# ISP6P5_RESIZER register map
Vendor: Texas Instruments
Peripheral module from a debugger description file (folder DRA74xP_75xP_76xP_77xP).
Registers are 32-bit, access per field, reset 0x0 unless marked. A register's access mark holds for its fields unless they carry their own. Offsets are as the file gives them; lines under a group give offsets from that group; [hi:lo] are bit positions; {n}, {i} and the like mark numbered series; 'fields as' and 'values as' point back to an identical list; <NAME> marks a mode.

## ISP6P5_RESIZER
0x00 RSZ_REVISION ro reset not defined — IP Revision Identifier (X.Y.R) Used by software to track features, bugs, and compatibility
  [31:0] REVISION — IP Revision
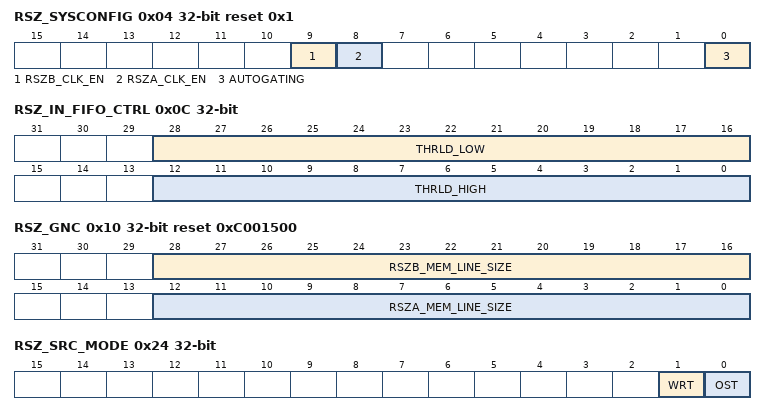
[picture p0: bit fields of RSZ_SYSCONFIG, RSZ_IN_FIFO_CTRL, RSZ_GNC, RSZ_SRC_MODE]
0x04 RSZ_SYSCONFIG reset 0x1 — SYSTEM CONFIGURATION REGISTER This register is not shadowed. There is no standalone software reset for the resizer module.
  [9] RSZB_CLK_EN rw — Resizer B clock enable This bit enable to enable / disable the RESIZER B clock. Note that it is a second level clock enable. This bit has effect only ifRSZ_GCK_SDR is set to '1'.
    0=NEWENUM1 (off); 1=NEWENUM2 (on)
  [8] RSZA_CLK_EN rw — Resizer A clock enable This bit enable to enable / disable the RESIZER A clock. Note that it is a second level clock enable. This bit has effect only ifRSZ_GCK_SDR is set to '1'.
    0=NEWENUM1 (off); 1=NEWENUM2 (on)
  [0] AUTOGATING rw — Internal Clock Gating Strategy Enables or disables auto clock gating.
    0=NEWENUM1 (Clocks are free running); 1=NEWENUM2 (Automatic clock gating strategy.)
0x08 RSZ_SYSSTATUS ro — SYSTEM STATUS REGISTER This register is not shadowed
0x0C RSZ_IN_FIFO_CTRL — INPUT DATA BUFFER CONTROL REGISTER This register is not shadowed
  [28:16] THRLD_LOW rw — WhenRSZ_IN_FIFO_CTRL.THRLD_HIGH = RSZ_IN_FIFO_CTRL.THRLD_LOW, the rsz_stall_input is not asserted. The only purpose of the RSZ_IN_FIFO_CTRL.THRLD_LOW register is to prevent rsz_stall_input signal assertion.
  [12:0] THRLD_HIGH rw — High threshold value. The rsz_stall_input signal is asserted if 2 lines of circular buffer are full and the third line has more pixels thanRSZ_IN_FIFO_CTRL.THRLD_HIGH. The rsz_stall_input signal stays high as long as one full line is not free for receiving further data. THRLD_HIGH is in terms of line size and can at max be programmed equal to the input line size (RSZ_SRC_HSZ).
0x10 RSZ_GNC ro reset 0xC001500 — GENERIC PARAMETER REGISTER
  [28:16] RSZB_MEM_LINE_SIZE — Resizer #B memory line size (pixels). The output image cannot exceed this size.
  [12:0] RSZA_MEM_LINE_SIZE — Resizer #A memory line size (pixels). The output image cannot excced this size.
0x14 RSZ_FRACDIV reset 0xFFFF — Fractional clock divider settings
  [15:0] RSZ_FRACDIV rw — Fractional clock divider value. The fractional clock divider gates the read requests made to the input data buffer such that the input data buffer is read at an average frequency equal to FFCLK instead of FCLK. The value of FFCLK depends upon the upscaling ratios as well as the input pixel clock: refer to the functional spec. We have FFCLK = FCLK / FRACDIV MHz andRSZ_FRACDIV = 65536 / FRACDIV. When RSZ_ FRACDIV = 65536, we have: FFCLK = FCLK.
0x20 RSZ_SRC_EN — RESIZER ENABLE REGISTER This register is not shadowed
  [0] EN rw — Resizer module enable The start flag of the RESIZER module. When EN is set to '1', the RESIZER module starts the processing from the next rising edge of the VD pulse. If the processing mode of the RESIZER module is set to 'one shot', the EN bit is cleared to '0' after the end of the processing. One has to pay attention that when this bit is enabled and
    0=NEWENUM1 (Disable); 1=NEWENUM2 (Enable)
0x24 RSZ_SRC_MODE — This register is not shadowed
  [1] WRT rw — Video port WEN signal selection This bit selects whether the WEN signal which is present on the IPIPE and IPIPEIF video port is used or not to select the input data. If WRT is 0, the RESIZER module ignores the WEN signal and processes all image frame while RESIZER is enabled. If WRT is 1, the RESIZER module only processes the lines that arrived while the WEN is high. HD is used to sample the WEN signal.
    0=NEWENUM1 (Disable); 1=NEWENUM2 (Enable)
  [0] OST rw — The processing mode selection of the RESIZER module. Value 0 indicates the mode of ?free run?, value 1 indicates the mode of ?one shot'.
    0=NEWENUM1 (Free running); 1=NEWENUM2 (One shot)
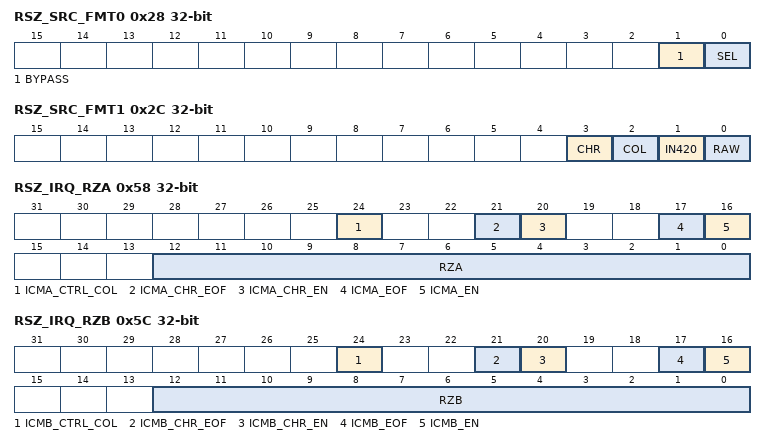
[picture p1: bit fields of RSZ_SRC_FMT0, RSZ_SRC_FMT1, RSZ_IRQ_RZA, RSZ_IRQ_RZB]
0x28 RSZ_SRC_FMT0 — This register is not shadowed
  [1] BYPASS rw — Pass Through This bit enables or disables the RESIZER module pass through mode. The pass trhough mode can transfer images which are 8K pixel wide. When it is enabled, the input data buffer and the resizer engines are bypassed.
    0=NEWENUM1 (Pass through off = normal output mode, the input data buffer is used.); 1=NEWENUM2 (Pass through on = normal output mode, the input data buffer is bypassed.)
  [0] SEL rw — Input selection This bit selects which of the two video port is selected to push data through the RESIZER module.
    0=NEWENUM1 (IPIPE); 1=SRC (IPIPEIF)
0x2C RSZ_SRC_FMT1
  [3] CHR rw — Cb/Cr order Note: This is only for OMA5430 This bit indicates if Cb/Cr is flipped. This bit is reffered by RGB output function. 0: Normal. Cb/Cr is in normal order. 1: Flipped. Cb/Cr is flipped. RGB output modules flips back Cb/Cr before applying YUV to RGB matrix.
    0=NORMAL (Cb/Cr is in normal order.); 1=FLIPPED (Cb/Cr is flipped. RGB output modules flips back Cb/Cr before applying YUV to RGB matrix.)
  [2] COL rw — Y/C selection This bit is valid only if the input data is YUV420 (IN420 = '1'). It enables to specify where the data which is input to the RESIZER module is luma or chroma data.
    0=NEWENUM1 (Y data is input); 1=NEWENUM2 (Chroma data is input)
  [1] IN420 rw — Chroma Format Selection This bit sets the chroma undersampling when YUV data is input to the RESIZER module.
    0=NEWENUM1 (YUV422 is input); 1=NEWENUM2 (YUV420 is input)
  [0] RAW rw — Pass-through mode input data format selection This bit affects the horizontal reversal (flipping) process.
    0=NEWENUM1 (Flipping preserves YCbCr format); 1=NEWENUM2 (Flipping preserves RAW format)
0x30 RSZ_SRC_VPS — VERTICAL POSITION REGISTER This register is not shadowed
  [15:0] VPS rw — Vertical Start Position Sets the vertical position of the global frame from the rising edge of the VD. The RSZ module will start the image processing from the VPS'th line. This value can be odd or even whatever the input data format.
0x34 RSZ_SRC_VSZ — VERTICAL SIZER REGISTER
  [12:0] VSZ rw — Vertical Processing Size Sets the vertical size of the processing area. The RSZ module will process (VSZ+1) lines. This value can be odd or even whatever the input data format.
0x38 RSZ_SRC_HPS — HORIZONTAL POSITION REGISTER This register is not shadowed
  [15:0] HPS rw — Horizontal Start Position TheRSZ_SRC_HPS register has two functions. The first function is to compensate for possible delay btw the HD pulse and the first valid data, it is possible that this delay be different of 0 when the RESIZER module gets its input data from the VPORT connected to the IPIPEIF module (the offset value can be odd or even). When data are coming from the IPIPE module, it is never required to resynchronize HD and first valid data. The second function is to crop the data in the horizontal direction. When used for cropping only RSZ_SRC_HPS shall be even or null.
0x3C RSZ_SRC_HSZ — HORIZONTAL SIZE REGISTER The HSZ value is given by HSZ concatenated with HSZ_LSB
  [12:0] HSZ rw — Horizontal size Sets the horizontal size of the processing area. The RSZ module processes (HSZ+1) pixels. (HSZ+1) shall be even for YUV422 and RAW data.
0x40 RSZ_DMA_RZA — RESIZER A - MEMORY REQUEST MINIMUM INTERVAL REGISTER
  [15:0] RZA rw — Sets the minimum inteval btw two consecutive memory request for resizer #A. Specified in number of interface clock cycles. Values of 0, 1, and 2 are used as a condition to keep the bandwidth limiter off. When this function is enabled, this value shall be greater than 10 cycles.
0x44 RSZ_DMA_RZB — RESIZER B - MEMORY REQUEST MINIMUM INTERVAL REGISTER
  [15:0] RZB rw — Sets the minimum inteval btw two consecutive memory request for resizer #B. Specified in number of interface clock cycles. Values of 0, 1, and 2 are used as a condition to keep the bandwidth limiter off. When this function is enabled, this value shall be greater than 10 cycles.
0x48 RSZ_DMA_STA ro — RESIZER STATUS REGISTER
  [0] STATUS — Resizer process status This bit is set in the time window from rsz_int_reg to rsz_int_dma.
    0=NEWENUM1 (Not active); 1=NEWENUM2 (Active)
0x4C RSZ_GCK_MMR — MMR CLOCK CONTROL REGISTER This register is not shadowed
  [0] MMR rw — The on/off selection of the MMR interface clock which is used for MMR register access.
    0=NEWENUM1 (Off); 1=NEWENUM2 (On)
0x54 RSZ_GCK_SDR — CORE CLOCK CONTROL REGISTER This register is not shadowed
  [0] CORE rw — RSZ Core Clock Enable. This bit enables or disables the resizer core functional clock. When this bit is off, the resizer core (interpolator) is automatically bypassed (resizer-bypass mode of pass-through mode is selected depending onRSZ_SRC_FMT0 value). In resizer-bypass mode or pass-through mode, no up-scaling or downscaling process is operated.
    0=NEWENUM1 (Resizer core clock disabled. Resizer in bypass mode if.BYPASS = 0 Resizer in pass-through if .BYPASS = 1); 1=NEWENUM2 (Resizer core clock enabled. Resizer in rescaling mode if.BYPASS = 0 Resizer in pass-through if .BYPASS = 1)
0x58 RSZ_IRQ_RZA — RESIZER A - CIRCULAR BUFFER INTERRUPT INTERVAL REGISTER
  [24] ICMA_CTRL_COL rw — Choose luma done (P_DONE_A) or chroma done (P_DONE_AC) to control
    0=LUMA (RZA processing is controlled by P_START and P_DONE_A (LUMA) This is used for cases not specified in CHROMA case.); 1=CHROMA (RZA processing is based on P_START and P_DONE_AC signal This case is chosen in the following cases - YUV422 input 420-Y+C output with CNF on - YUV422 input 420-C output - YUV420-C input 420-C output)
  [21] ICMA_CHR_EOF rw — Enable the generation of P_DONE_AC pulse at the end of each frame, if the height is not a multiple of RZA. For example, generate a pulse at the end of frme if the height is 1080 and RZA=256. This is only valid if ICMA_CHR_EN='1'
    0=DISABLE (Don't generate a P_DONE_A pulse at the end of frame if the height is not a multiple of RZA); 1=ENABLE (Generate a P_DONE_A pulse at the end of frame if the height is not a multiple of RZA)
  [20] ICMA_CHR_EN rw — Enable hand-shaking with ICM (RSZ-A) in Chroma Channel This is only valid in YUV-420 mode with chroma output. In particular, in the following 2 cases 1. YUV422 input YUV420 outputRSZ_SRC_FMT1.IN420 = 0 (YUV 422 input) RZA_420.CEN = 1 (YUV420 output. Chroma output enabled) ICM cycle is 1/2 of the value specified in RZA 2. YUV420 Chroma input/output RSZ_SRC_FMT1.IN420 = 1 (YUV 420 input) RSZ_SRC_FMT1.COL = 1 (Chroma input) ICM cycle is the cycle specified by RZA
    0=DISABLE (Disable handshake between RSZA and ICM); 1=ENABLE (Enable handshake between RSZA and ICM)
  [17] ICMA_EOF rw — Enable the generation of P_DONE_A pulse at the end of each frame, if the height is not a multiple of RZA. For example, generate a pulse at the end of frme if the height is 1080 and RZA=256. This is only valid if ICMA_EN='1'
    values as ICMA_CHR_EOF
  [16] ICMA_EN rw — Enable hand-shaking with ICM (RSZ-A)
    values as ICMA_CHR_EN
  [12:0] RZA rw — Resizer A circular buffer interval. This value is also used as a ICM-RSZA hand shake interval. Sets the circular buffer interval for Resizer A. The interrupt is triggered everytime (RZA+1) lines are written to the circular buffer (Y buffer). The range goes from 1 to 8192 lines. Usually, the circular buffer vertical size should be a multiple of RZA.
0x5C RSZ_IRQ_RZB — RESIZER B - CIRCULAR BUFFER INTERRUPT INTERVAL REGISTER
  [24] ICMB_CTRL_COL rw — Choose luma done (P_DONE_B) or chroma done (P_DONE_BC) to control
    0=LUMA (RZB processing is controlled by P_START and P_DONE_B (LUMA) This is used for cases not specified in CHROMA case.); 1=CHROMA (RZB processing is based on P_START and P_DONE_BC signal This case is chosen in the following cases - YUV422 input 420-Y+C output with CNF on - YUV422 input 420-C output - YUV420-C input 420-C output)
  [21] ICMB_CHR_EOF rw — Enable the generation of P_DONE_BC pulse at the end of each frame, if the height is not a multiple of RZB. For example, generate a pulse at the end of frme if the height is 1080 and RZB=256. This is only valid if ICMB_CHR_EN='1'
    values as RSZ_IRQ_RZA.ICMA_CHR_EOF
  [20] ICMB_CHR_EN rw — Enable hand-shaking with ICM (RSZ-B) in Chroma Channel This is only valid in YUV-420 mode with chroma output. In particular, in the following 2 cases 1. YUV422 input YUV420 outputRSZ_SRC_FMT1.IN420 = 0 (YUV 422 input) RZB_420.CEN = 1 (YUV420 output. Chroma output enabled) ICM cycle is 1/2 of the value specified in RZB 2. YUV420 Chroma input/output RSZ_SRC_FMT1.IN420 = 1 (YUV 420 input) RSZ_SRC_FMT1.COL = 1 (Chroma input) ICM cycle is the value specified in RZB
    values as RSZ_IRQ_RZA.ICMA_CHR_EN
  [17] ICMB_EOF rw — Enable the generation of P_DONE_B pulse at the end of each frame, if the height is not a multiple of RZB. For example, generate a pulse at the end of frme if the height is 1080 and RZB=256. This is only valid if ICMB_EN='1'
    0=DISABLE (Don't generate a P_DONE_B pulse at the end of frame if the height is not a multiple of RZB.); 1=ENABLE (Generate a P_DONE_B pulse at the end of frame if the height is not a multiple of RZB.)
  [16] ICMB_EN rw — Enalbe handshake between RSZB and ICM
    0=DISABLE (Disable handshake between RSZB and ICM); 1=ENABLE (Enable handshake between RSZB and ICM)
  [12:0] RZB rw — Resizer B circular buffer interval. This value is also used as a ICM-RSZB hand shake interval. Sets the circular buffer interval for Resizer B. The interrupt is triggered everytime (RZB+1) lines are written to the circular buffer (Y buffer). The range goes from 1 to 8192 lines. Usually, the circular buffer vertical size should be a multiple of RZB.
0x60 RSZ_YUV_Y_MIN — LUMINANCE SATURATION REGISTER
  [7:0] MIN rw — The minimum value of Luminance (8bits unsigned). If the value of the Luminance is smaller than VAL, it will be clipped to VAL. This bit field shall be set to its default values when the resizer is set in pass-though mode.
0x64 RSZ_YUV_Y_MAX reset 0xFF — LUMINANCE SATURATION REGISTER
  [7:0] MAX rw — The maximum value of Luminance (8bits unsigned). If the value of the Luminance is larger than VAL, it will be clipped to VAL. This bit field shall be set to its default values when the resizer is set in pass-through mode.
0x68 RSZ_YUV_C_MIN — CHROMINANCE SATURATION REGISTER
  [7:0] MIN rw — The minimum value of Chrominance (8bits unsigned). If the value of the Chrominance is smaller than VAL, it will be clipped to VAL. This bit field shall be set to its default values when the resizer is set in pass-though mode.
0x6C RSZ_YUV_C_MAX reset 0xFF — CHROMINANCE SATURATION REGISTER
  [7:0] MAX rw — The maximum value of Chrominance (8bits unsigned). If the value of the Chrominance is larger than VAL, it will be clipped to VAL. This bit field shall be set to its default values when the resizer is set in pass-through mode.
0x70 RSZ_YUV_PHS — The phase position of the output of the Chrominance
  [0] POS rw — The phase position of the output of the chrominance. The RESIZER module does not change the relative position of the chroma samples vs. the luma samples between the input and output and the chroma position at the output of the IPIPE module and at the output of the RESIZER module shall be identical. In other words, we shall haveRSZ_YUV_PHS.POS = IPIPE_YUV_PHS.POS.
    0=NEWENUM1 (Same position with Luminance: cosited); 1=NEWENUM2 (The middle of the luminance: centered)
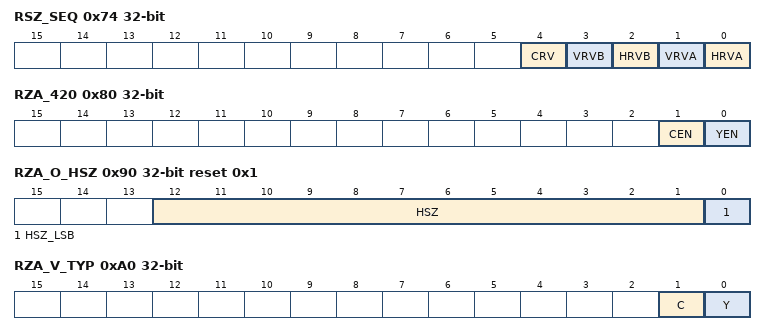
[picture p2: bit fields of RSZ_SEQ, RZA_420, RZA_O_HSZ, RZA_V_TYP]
0x74 RSZ_SEQ
  [4] CRV rw — Chroma sampling point change
    0=NEWENUM1 (Chroma sampling point is not changed); 1=NEWENUM2 (Chroma sampling point is changed from odd-numbered pixels to even-number pixels. The pixel at the left end is removed and the pixel at the right end is duplicated.)
  [3] VRVB rw — Resizer B - Vertical reversal of output image
    0=NEWENUM1 (Processed pixels are output in the order of input (normal operation) in vertical direction.); 1=NEWENUM2 (The order of output data is flipped top to bottom.)
  [2] HRVB rw — Resizer B -Horizontal reversal of output image
    0=NEWENUM1 (Processed pixels are output in the order of input (normal operation) in horizontal direction.); 1=NEWENUM2 (The order of output data is flipped left to right.)
  [1] VRVA rw — Resizer A - Vertical reversal of output image
    values as VRVB
  [0] HRVA rw — Resizer A - Horizontal reversal of output image
    values as HRVB
0x78 RZA_EN — RESIZER A - ENABLE REGISTER
  [0] EN rw — Enable resizer #A This bit is latched on video port VD input. The reason is that the resizer shall only starts the processing on a clean frame boundary. In one-shot mode, this bit is negated on VD.
    0=NEWENUM1 (Disable); 1=NEWENUM2 (Enable)
0x7C RZA_MODE — RESIZER #A MODE REGISTER
  [0] MODE rw — Select 'Free Run mode' or 'One Shot Mode'
    0=NEWENUM1 (Free run); 1=NEWENUM2 (One shot)
0x80 RZA_420 — YEN/CEN: 0/0: in = YUV422 input, out = YUV422 output 0/1: in = YUV422 input, out = Chrominance of YUV420 output 1/0: in = YUV422 input, out = Luminance of YUV420 output 1/1: in = YUV422 input, out = YUV420 output
  [1] CEN rw — Output Enable for Chrominance This bit is valid in 422 input mode.When CEN=0 and YEN=0, output is 422
    0=NEWENUM1 (C output disable); 1=NEWENUM2 (C output enable and 422to420 conversion enabled)
  [0] YEN rw — Output Enable for Luminance This bit is valid in 422 input mode.When CEN=0 and YEN=0, output is 422
    0=NEWENUM1 (Y output disable); 1=NEWENUM2 (Y output enable and 422to420 conversion enabled)
0x84 RZA_I_VPS — RESIZER A - INPUT VERTICAL START REGISTER Note: The height of the image after the second crop must be 2 or larger.
  [12:0] VPS rw — Input Vertical Position Sets the vertical start position of the input image within the global frame. It enables to crop data into the global frame. After SRC_VPS, the Vps'th line is processed as the first line in each image. Note: after the second level crop, the height of the image area must be two or larger, i.e. one-line image is not allowed. (RSZ_VSZ -RZA_I_VPS 0)
0x88 RZA_I_HPS — RESIZER A - INPUT HORIZONTAL START REGISTER
  [12:0] HPS rw — Input Horizontal Position Sets the horizontal position of the first pixel for each line within the global frame. After SRC_HPS, the pixel at the VAL'th position is processed as the first pixel. This value shall be even.
0x8C RZA_O_VSZ — RESIZER A - OUTPUT VERTICAL SIZE REGISTER In 422 to 420 mode, chorma output lines number is 1/2 of this value. When CNFA is enabled, this value must be - x2 of CNFA height, if CDS if off. The value is always even - x4 of CNFA height, if CDS is on. The value is alway a multiple of 4 CNFA width are specified in.HEIGHT in ISP6_SYS3, and .IH in CNF1, which must be always identical to each other.
  [12:0] VSZ rw — The target output size of the resized image. The number of output lines is (VSZ+1). Set 479, when 480 lines of output is required.
0x90 RZA_O_HSZ reset 0x1 — RESIZER A - OUTPUT HORIZONTAL SIZE REGISTER When CNFA is enabled, this value must be - Same as CNFA width, if CDS is off. The value is always even - x2 of CNFA width, if CDS is on. The value is always a multiple of 4 CNFA width are specified in.WIDTH in ISP6_SYS3, and .IW in CNF1, which must be always identical to each other.
  [12:1] HSZ rw — The horizontal size of output image. The number of pixel in each line is (HSZ+1). Set 479, when 480 pixels are required. This value must be lower than the max memory line size supported by the resizer engine, except in RAW pass through mode. Note that the LSB of the 13-bit HSZ value is fixed to 1 such that the horizontal size is always even.
  [0] HSZ_LSB ro — The least significant bit of HSZ is forced to 1.
0x94 RZA_V_PHS_Y — RESIZER A - INITIAL LUMINANCE PHASE OF VERTICAL RESIZING PROCESS When YUV422 data are output, the phase values for luma and chroma should typicall be equal, i.e., RZX_V_PHS_Y= RZX_V_PHS_C. The following constraints apply when setting the initial vertical phases ABS(RZX_V_PHS_Y - RZX_V_PHS_C) ? RZX_V_DIF. This constraint means that at most the distance between the initial phases for luminance and chrominance is not expected to exceed the distance between two luma pixels. Note that the absolute value is used, hence, the initial luma phase can be greater than the initial chroma phase or the other way around. As a reminder, the distance between two output pixels for luma is given by RZX_V_DIF.
  [13:0] Y rw — The initial value for the luma phase in vertical resizing process. This value is in U14Q8 fractional format.
0x98 RZA_V_PHS_C — RESIZER A - INITIAL CHROMINANCE PHASE OF VERTICAL RESIZING PROCESS When YUV422 data are output, the phase values for luma and chroma should typicall be equal, i.e., RZX_V_PHS_Y= RZX_V_PHS_C. The following constraints apply when setting the initial vertical phases ABS(RZX_V_PHS_Y - RZX_V_PHS_C) ? RZX_V_DIF. This constraint means that at most the distance between the initial phases for luminance and chrominance is not expected to exceed the distance between two luma pixels. Note that the absolute value is used, hence, the initial luma phase can be greater than the initial chroma phase or the other way around. As a reminder, the distance between two output pixels for luma is given by RZX_V_DIF.
  [13:0] C rw — The initial value for the chroma phase in vertical resizing process. This value is in U14Q8 fractional format.
0x9C RZA_V_DIF — RESIZER A - VERTICAL RESIZER REGISTER
  [13:0] V rw — The parameter for vertical resize. The actual resizing ratio is 256/RZA_V_DIF. In normal mode: 16 = RZA_V_DIF = 4096. In down-scale mode: 256 = RZA_V_DIF = 4096.
0xA0 RZA_V_TYP — RESIZER A - INTERPOLATION METHOD FOR VERTICAL RESIZING
  [1] C rw — Selection of resizing method for chrominance: vertical
    0=NEWENUM1 (4-tap cubic convolution (default)); 1=NEWENUM2 (2-tap linear interpolation)
  [0] Y rw — Selection of resizing method for luminance: vertical
    values as C
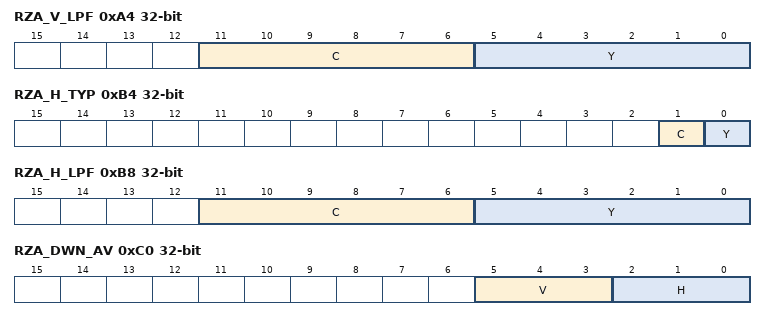
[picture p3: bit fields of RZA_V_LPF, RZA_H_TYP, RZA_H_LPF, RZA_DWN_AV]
0xA4 RZA_V_LPF — RESIZER A - VERTICAL LPF INTENSITY REGISTER
  [11:6] C rw — The intensity parameter for chroma vertical low pass filtering.
  [5:0] Y rw — The intensity parameter for luma vertical low pass filtering.
0xA8 RZA_H_PHS — RESIZER A - INITIAL PHASE OF HORIZONTAL RESIZING PROCESS
  [13:0] PHS rw — Initial value for the phase in horizontal resizing process, i.e., the sampling position is shifted. This value is in U14Q8 fractional format. Example: If RZX_H_PHS = 128, the first output pixel is sampled at the center of the first two valid input pixels. If RZX_I_HPS=100 and RZX_H_PHS=128, the first output pixel is re-sampled at the center of the 100-th and the 101-st input pixels.
0xAC RZA_H_PHS_ADJ — RESIZER A - LUMINANCE HORIZONTAL PHASE ADJUSTMENT The register enables to adjust the horizontal phase for the luma component when averaging is enabled (the horizontal averaging disrupts the relative sampling point between luminance and chrominance when YUV422 cosited data is input), i.e., the relative phase between luma and chroma is different before and after the horizontal averager.
  [8:0] ADJ rw — Horizontal phase adjustment value. This value is in U9Q8 fractional format. This value is expected to be equal to zero if the averager is disabled or if input chroma is centered.
0xB0 RZA_H_DIF — RESIZER A - HORIZONTAL RESIZER REGISTER
  [13:0] H rw — The parameter for horizontal resizing process. The actual resizing ratio is 256/VAL. In normal mode 16 = RSZ_RZA_H_DIF =4096 In down-scale mode 256 =RSZ_RZA_H_DIF =4096
0xB4 RZA_H_TYP — Resize-A
  [1] C rw — Selection of resizing method for chrominance: horizontal
    values as RZA_V_TYP.C
  [0] Y rw — Selection of resizing method for luminance: horizontal
    values as RZA_V_TYP.C
0xB8 RZA_H_LPF — RESIZER A - HORIZONTAL LPF INTENSITY REGISTER
  [11:6] C rw — Horizontal LPF Intensity for Chrominance
  [5:0] Y rw — Selection of resizing method for Luminance in horizontal direction
0xBC RZA_DWN_EN — RESIZER #A - DOWNSCALE ENABLE REGISTER
  [0] DWN_EN rw — Resizer downscale enable
    0=NEWENUM1 (Off. Normal operation: upscale and downscale are allowed.); 1=NEWENUM2 (On. Downscale mode.)
0xC0 RZA_DWN_AV — Resize-A
  [5:3] V rw — Vertical averaging size : 1/2^(VWT+1) The range goes from 1/2 to 1/256 in power of two. 0:_DIV21/2 down scale 1:_DIV41/4 down scale 2:_DIV81/8 down scale 3:_DIV161/16 down scale 4:_DIV321/32 down scale 5:_DIV641/64 down scale 6:_DIV1281/128 down scale 7:_DIV2561/256 down scale
  [2:0] H rw — Horizontal averaging size : 1/2^(HWT+1) The range goes from 1/2 to 1/256 in power of two. 0:_DIV21/2 down scale 1:_DIV41/4 down scale 2:_DIV81/8 down scale 3:_DIV161/16 down scale 4:_DIV321/32 down scale 5:_DIV641/64 down scale 6:_DIV1281/128 down scale 7:_DIV2561/256 down scale
0xC4 RZA_RGB_EN — RESIZER #A - RGB OUTPUT ENABLE
  [0] RGB_EN rw — Enable of RGB output In pass through mode, this register must be 0. This bit can only be set to 1 when YUV422 data are output. YUV422 data output is selected when SRC_FMT1.IN420 = 0 andRZA_420.YEN = RZA_420.CEN = 0
    0=NEWENUM1 (Off (YCbCr output)); 1=NEWENUM2 (On (RGB output))
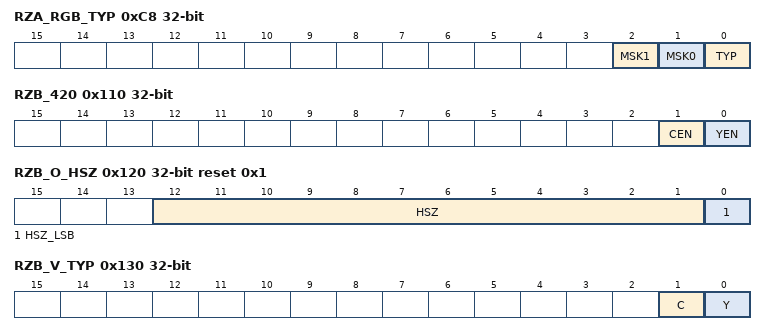
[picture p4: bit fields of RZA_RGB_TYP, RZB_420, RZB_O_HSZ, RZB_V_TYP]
0xC8 RZA_RGB_TYP — RESIZER A - RGB OUTPUT CONTROL REGISTER
  [2] MSK1 rw — Enables masking of the last 2 pixels This bit is used to mask the 2 last pixels at the image boundary which are affected by the YUV422 to YUV444 conversion.
    0=NEWENUM1 (output the last 2 pixels); 1=NEWENUM2 (mask the last 2 pixels (Resizer do not output them.))
  [1] MSK0 rw — Enables masking of the first 2 pixels This bit is used to mask the 2 first pixels at the image boundary which are affected by the YUV422 to YUV444 conversion.
    0=NEWENUM1 (output the first 2 pixels); 1=NEWENUM2 (mask the first 2 pixels (Resizer do not output them.))
  [0] TYP rw — 16bit/32bit output selection
    0=NEWENUM1 (32-bit output: alpha + R + G + B (8 bit each) This mode comes with performance degradation. The maximum input frequency in this mode is 160 MHz. This due to the fact that the output is 4 bytes / pixel.); 1=NEWENUM2 (16-bit output: R(5 bit) + G (6 bit) + B (5 bit))
0xCC RZA_RGB_BLD — RESIZER A - RGB BLEND REGISTER
  [7:0] BLD rw — The alpha value used in 32-bit RGBA output mode
0xD0 RZA_SDR_Y_BAD_H — RESIZER A - OUTPUT MEMORY BASE ADDRESS REGISTER (HIGH) This register is used if the output data format is one of the following: RAW, YUV422, YUV420, RGB565, RGBA. RAW: RAW data is written to this address YUV422: YUV data is written to this address YUV420: Y data is written to this address RGB565: 16-bit RGB data is written to this address RGBA: 32-bit RGBA data is written to this address
  [15:0] Y_BAD_H rw — Memory Base Address Sets the 16 upper bits of the 32-bit base address of the circular buffer in memory.
0xD4 RZA_SDR_Y_BAD_L — RESIZER A - OUTPUT MEMORY BASE ADDRESS REGISTER (LOW) This register is used if the output data format is one of the following: RAW, YUV422, YUV420, RGB565, RGBA. RAW: RAW data is written to this address YUV422: YUV data is written to this address YUV420: Y data is written to this address RGB565: 16-bit RGB data is written to this address RGBA: 32-bit RGBA data is written to this address
  [15:0] Y_BAD_L rw — Memory Base Address Sets the 16 lower bits of the 32-bit base address of the circular buffer in memory. It is a byte address. YUV420 format (output data on 8 bits): The two least significant bits shall be set to '00' when horizontal reversal mode is off. The two least significant bits shall be set to '11' when horizontal reversal mode is on. RAW, RGB565 and YUV422 formats (output data on 16 bits): The two least significant bits shall be set to '00' when horizontal reversal mode is off. The two least significant bits shall be set to '11' when horizontal reversal mode is on. RGBA format (output data on 32 bits): The three least significant bits shall be set to '000' when horizontal reversal mode is off. The three least significant bits shall be set to '111' when horizontal reversal mode is on.
0xD8 RZA_SDR_Y_SAD_H — RESIZER A - OUTPUT MEMORY START ADDRESS REGISTER (HIGH) This register is used if the output data format is one of the following: RAW, YUV422, YUV420, RGB565, RGBA. RAW: RAW data is written to this address YUV422: YUV data is written to this address YUV420: Y data is written to this address RGB565: 16-bit RGB data is written to this address RGBA: 32-bit RGBA data is written to this address
  [15:0] Y_SAD_H rw — Memory Start Address Sets the 16 upper bits of the 32-bit start address in memory.
0xDC RZA_SDR_Y_SAD_L — RESIZER A - OUTPUT MEMORY START ADDRESS REGISTER (LOW) This register is used if the output data format is one of the following: RAW, YUV422, YUV420, RGB565, RGBA. RAW: RAW data is written to this address YUV422: YUV data is written to this address YUV420: Y data is written to this address RGB565: 16-bit RGB data is written to this address RGBA: 32-bit RGBA data is written to this address
  [15:0] Y_SAD_L rw — Memory Start Address Sets 16 lower bits of the 32-bit start address in memory. It is a byte address. For every frame, the first line of data will be written to this address. We have: SAD = BAD + (PTR_S x OFT) and PTR_S PTR_E If the first line shall be written at the beginning of the circular buffer memory then SAD = BAD and PTR_S = 0. YUV420 format (output data on 8 bits): The two least significant bits shall be set to '00' when horizontal reversal mode is off. The two least significant bits shall be set to '11' when horizontal reversal mode is on. RAW, RGB565 and YUV422 formats (output data on 16 bits): The two least significant bits shall be set to '00' when horizontal reversal mode is off. The two least significant bits shall be set to '11' when horizontal reversal mode is on. RGBA format (output data on 32 bits): The three least significant bits shall be set to '000' when horizontal reversal mode is off. The three least significant bits shall be set to '111' when horizontal reversal mode is on.
0xE0 RZA_SDR_Y_OFT — RESIZER A - OUTPUT MEMORY OFFSET REGISTER This register is used if the output data format is one of the following: RAW, YUV422, YUV420 or RGBA.
  [16:0] Y_OFT rw — Memory Line Offset Sets the size of each line in the circular buffer. It is expressed in bytes and unsigned. Note that OFT does not necessary corresponds to the size of a line in a frame, it can be much bigger. The line offset shall be a multiple of 128 bytes (bits [6:0] of RZX_SDR_Y_OFT and RZX_SDR_C_OFT shall be set to 0). Example: line 0 address = SAD line 1 address = SAD + 1 x OFT line 2 address = SAD + 2 x OFT
0xE4 RZA_SDR_Y_PTR_S — RESIZER A - OUTPUT MEMORY START ADDRESS REGISTER This register is used if the output data format is one of the following: RAW, YUV422, YUV420 or RGBA.
  [12:0] Y_PTR_S rw — Start Line of Memory Pointer Sets the vertical position of the first output line in the output memory space. This value is expressed in number of lines. The hw uses it to setup the initial value of the circular buffer. It shall be setup such as PTR_S = (SAD ? BAD) / OFT. This value shall be set to 0 when RSZ_RZA_SDR_Y_BAD = RSZ_RZA_SDR_Y_SAD.
0xE8 RZA_SDR_Y_PTR_E — RESIZER A - OUTPUT MEMORY END ADDRESS REGISTER This register is used if the output data format is one of the following: RAW, YUV422, YUV420 or RGBA.
  [12:0] Y_PTR_E rw — End Line of Memory Pointer Sets the maximum number of lines to be stored in the output memory space. This value is expressed in number of lines. When the number of output lines exceeds this value, the address restarts from the first address in the output memory space (BAD).
0xEC RZA_SDR_C_BAD_H — RESIZER A - OUTPUT MEMORY BASE ADDRESS REGISTER FOR CHROMA DATA (YUV420) This register is used if the output data format is YUV420. U and V data are written into this buffer.
  [15:0] C_BAD_H rw — Memory Base Address Sets the 16 higher bits of the 32-bit base address of the circular buffer in memory.
0xF0 RZA_SDR_C_BAD_L — RESIZER A - OUTPUT MEMORY BASE ADDRESS REGISTER FOR CHROMA DATA (YUV420) This register is used if the output data format is YUV420. U and V data are written into this buffer.
  [15:0] C_BAD_L rw — Memory Base Address Sets the 16 lower bits of the 32-bit base address of the circular buffer in memory. It is a byte address. YUV420 format (output data on 8 bits): The two least significant bits shall be set to '00' when horizontal reversal mode is off. The two least significant bits shall be set to '11' when horizontal reversal mode is on.
0xF4 RZA_SDR_C_SAD_H — RESIZER A - OUTPUT MEMORY START ADDRESS REGISTER FOR CHROMA DATA (YUV420) This register is used if the output data format is YUV420. U and V data are written into this buffer.
  [15:0] C_SAD_H rw — Memory Base Address Sets the 16 higher bits of the 32-bit start address in memory.
0xF8 RZA_SDR_C_SAD_L — RESIZER A - OUTPUT MEMORY START ADDRESS REGISTER FOR CHROMA DATA (YUV420) This register is used if the output data format is YUV420. U and V data are written into this buffer.
  [15:0] C_SAD_L rw — Memory Base Address Sets the 16 lower bits of the 32-bit start address in memory. It is a byte address. For every frame, the first line of data will be written to this address. We have: SAD = BAD + (PTR_S x OFT) and PTR_S PTR_E If the first line shall be written at the beginning of the circular buffer memory then SAD = BAD and PTR_S = 0. YUV420 format (output data on 8 bits): The two least significant bits shall be set to '00' when horizontal reversal mode is off. The two least significant bits shall be set to '11' when horizontal reversal mode is on.
0xFC RZA_SDR_C_OFT — RESIZER A - OUTPUT MEMORY OFFSET REGISTER FOR CHROMA DATA (YUV420) This register is used if the output data format is YUV420
  [16:0] C_OFT rw — Memory Line Offset Sets the size of each line in the circular buffer. It is expressed in bytes and unsigned. Note that OFT does not necessary corresponds to the size of a line in a frame, it can be much bigger. The line offset shall be a multiple of 128 bytes (bits [6:0] of RZX_SDR_Y_OFT and RZX_SDR_C_OFT shall be set to 0). Example: line 0 address = SAD line 1 address = SAD + 1 x OFT line 2 address = SAD + 2 x OFT
0x100 RZA_SDR_C_PTR_S — RESIZER A - OUTPUT MEMORY START ADDRESS REGISTER FOR CHROMA DATA (YUV420) This register is used if the output data format is YUV420
  [12:0] C_PTR_S rw — Start Line of Memory Pointer Sets the vertical position of the first output line in the output memory space. This value is expressed in number of lines. The hw uses it to setup the initial value of the circular buffer. It shall be setup such as PTR_S = (SAD ? BAD) / OFT. This value shall be set to 0 when RSZ_RZA_SDR_C_BAD = RSZ_RZA_SDR_C_SAD.
0x104 RZA_SDR_C_PTR_E — RESIZER A - OUTPUT MEMORY END ADDRESS REGISTER FOR CHROMA DATA (YUV420) This register is used if the output data format is YUV420
  [12:0] C_PTR_E rw — End Line of Memory Pointer Sets the maximum number of lines to be stored in the output memory space. This value is expressed in number of lines. When the number of output lines exceeds this value, the address restarts from the first address in the output memory space (BAD).
0x108 RZB_EN — RESIZER B - ENABLE REGISTER
  [0] EN rw — Enable resizer #A This bit is latched on the video port VD input signal. The reason is that the resizer shall only starts the processing on a clean frame boundary. In one-shot mode, this bit is negated on VD.
    0=NEWENUM1 (Disable); 1=NEWENUM2 (Enable)
0x10C RZB_MODE — RESIZER B MODE REGISTER
  fields as RZA_MODE
0x110 RZB_420 — YEN/CEN: 0/0: in = YUV422 input, out = YUV422 output 0/1: in = YUV422 input, out = Chrominance of YUV420 output 1/0: in = YUV422 input, out = Luminance of YUV420 output 1/1: in = YUV422 input, out = YUV420 output
  fields as RZA_420
0x114 RZB_I_VPS — RESIZER B - INPUT VERTICAL START REGISTER Note: The height of the image after the second crop must be 2 or larger.
  [12:0] VPS rw — Input Vertical Position Sets the vertical start position of the input image within the global frame. It enables to crop data into the global frame. After SRC_VPS, the Vps'th line is processed as the first line in each image. Note: after the second level crop, the height of the image area must be two or larger, i.e. one-line image is not allowed. (RSZ_VSZ -RZB_I_VPS 0)
0x118 RZB_I_HPS — RESIZER B - INPUT HORIZONTAL START REGISTER
  fields as RZA_I_HPS
0x11C RZB_O_VSZ — RESIZER B - OUTPUT VERTICAL SIZER REGISTER In 422 to 420 mode, chorma output lines number is 1/2 of this value. When CNFB is enabled, this value must be - x2 of CNFB height, if CDS if off. The value is always even - x4 of CNFB height, if CDS is on. The value is alway a multiple of 4 CNFB width are specified in.HEIGHT in ISP6_SYS3, and .IH in CNF2, which must be always identical to each other.
  fields as RZA_O_VSZ
0x120 RZB_O_HSZ reset 0x1 — RESIZER B - OUTPUT HORIZONTAL SIZE REGISTER When CNFB is enabled, this value must be - Same as CNFB width, if CDS is off. The value is always even - x2 of CNFB width, if CDS is on. The value is always a multiple of 4 CNFB width are specified in.WIDTH in ISP6_SYS3, and .IW in CNF2, which must be always identical to each other.
  fields as RZA_O_HSZ
0x124 RZB_V_PHS_Y — RESIZER B - INITIAL LUMINANCE PHASE OF VERTICAL RESIZING PROCESS When YUV422 data are output, the phase values for luma and chroma should typicall be equal, i.e., RZX_V_PHS_Y= RZX_V_PHS_C. The following constraints apply when setting the initial vertical phases ABS(RZX_V_PHS_Y - RZX_V_PHS_C) ? RZX_V_DIF. This constraint means that at most the distance between the initial phases for luminance and chrominance is not expected to exceed the distance between two luma pixels. Note that the absolute value is used, hence, the initial luma phase can be greater than the initial chroma phase or the other way around. As a reminder, the distance between two output pixels for luma is given by RZX_V_DIF.
  fields as RZA_V_PHS_Y
0x128 RZB_V_PHS_C — RESIZER B - INITIAL CHROMINANCE PHASE OF VERTICAL RESIZING PROCESS When YUV422 data are output, the phase values for luma and chroma should typicall be equal, i.e., RZX_V_PHS_Y= RZX_V_PHS_C. The following constraints apply when setting the initial vertical phases ABS(RZX_V_PHS_Y - RZX_V_PHS_C) ? RZX_V_DIF. This constraint means that at most the distance between the initial phases for luminance and chrominance is not expected to exceed the distance between two luma pixels. Note that the absolute value is used, hence, the initial luma phase can be greater than the initial chroma phase or the other way around. As a reminder, the distance between two output pixels for luma is given by RZX_V_DIF.
  fields as RZA_V_PHS_C
0x12C RZB_V_DIF — RESIZER B - VERTICAL RESIZER REGISTERR
  [13:0] V rw — The parameter for vertical resize. The actual resizing ratio is 256/RZB_V_DIF. In normal mode: 16 = RZB_V_DIF = 4096. In down-scale mode: 256 = RZB_V_DIF = 4096.
0x130 RZB_V_TYP — RESIZER B - INTERPOLATION METHOD FOR VERTICAL RESIZING
  fields as RZA_V_TYP
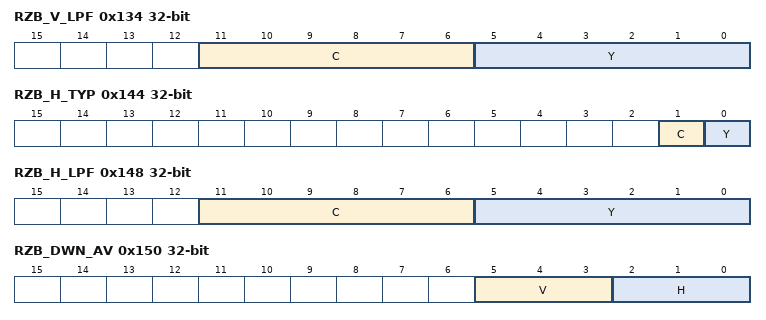
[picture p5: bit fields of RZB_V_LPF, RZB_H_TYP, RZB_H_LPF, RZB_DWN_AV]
0x134 RZB_V_LPF — RESIZER B - VERTICAL LPF INTENSITY REGISTER
  fields as RZA_V_LPF
0x138 RZB_H_PHS — RESIZER B - INITIAL PHASE OF HORIZONTAL RESIZING PROCESS
  fields as RZA_H_PHS
0x13C RZB_H_PHS_ADJ — RESIZER B - LUMINANCE HORIZONTAL PHASE ADJUSTMENT The register enables to adjust the horizontal phase for the luma component when averaging is enabled (the horizontal averaging disrupts the relative sampling point between luminance and chrominance when YUV422 cosited data is input), i.e., the relative phase between luma and chroma is different before and after the horizontal averager.
  fields as RZA_H_PHS_ADJ
0x140 RZB_H_DIF — RESIZER B - HORIZONTAL RESIZER REGISTER
  fields as RZA_H_DIF
0x144 RZB_H_TYP — RESIZER B
  fields as RZA_H_TYP
0x148 RZB_H_LPF — RESIZER B - HORIZONTAL LPF INTENSITY REGISTER
  fields as RZA_H_LPF
0x14C RZB_DWN_EN — RESIZER B - DOWNSCALE ENABLE REGISTER
  fields as RZA_DWN_EN
0x150 RZB_DWN_AV — RESIZER B
  fields as RZA_DWN_AV
0x154 RZB_RGB_EN — RESIZER B - RGB OUTPUT ENABLE
  [0] RGB_EN rw — Enable of RGB output In pass through mode, this register must be 0. This bit can only be set to 1 when YUV422 data are output. YUV422 data output is selected when SRC_FMT1.IN420 = 0 andRZB_420.YEN = RZB_420.CEN = 0
    values as RZA_RGB_EN.RGB_EN
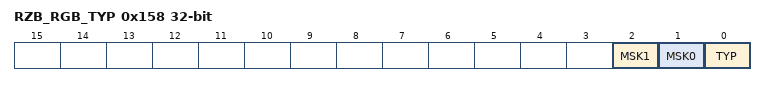
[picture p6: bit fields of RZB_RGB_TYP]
0x158 RZB_RGB_TYP — RESIZER B - RGB OUTPUT CONTROL REGISTER
  fields as RZA_RGB_TYP
0x15C RZB_RGB_BLD — RESIZER B - RGB BLEND REGISTER
  [7:0] BLD rw — The alpha value used in 32-bit RGBA output mode
0x160 RZB_SDR_Y_BAD_H — RESIZER B - OUTPUT MEMORY BASE ADDRESS REGISTER This register is used if the output data format is one of the following: RAW, YUV422, YUV420, RGB565, RGBA. RAW: RAW data is written to this address YUV422: YUV data is written to this address YUV420: Y data is written to this address RGB565: 16-bit RGB data is written to this address RGBA: 32-bit RGBA data is written to this address
  [15:0] Y_BAD_H rw — Memory Base Address Sets 16 upper bits of the 32-bit base address of the circular buffer in memory.
0x164 RZB_SDR_Y_BAD_L — RESIZER B - OUTPUT MEMORY BASE ADDRESS REGISTER This register is used if the output data format is one of the following: RAW, YUV422, YUV420, RGB565, RGBA. RAW: RAW data is written to this address YUV422: YUV data is written to this address YUV420: Y data is written to this address RGB565: 16-bit RGB data is written to this address RGBA: 32-bit RGBA data is written to this address
  fields as RZA_SDR_Y_BAD_L
0x168 RZB_SDR_Y_SAD_H — RESIZER B - OUTPUT MEMORY START ADDRESS REGISTER This register is used if the output data format is one of the following: RAW, YUV422, YUV420, RGB565, RGBA. RAW: RAW data is written to this address YUV422: YUV data is written to this address YUV420: Y data is written to this address RGB565: 16-bit RGB data is written to this address RGBA: 32-bit RGBA data is written to this address
  [15:0] Y_SAD_H rw — Memory Start Address Sets 16 upper bits of the 32-bit start address in memory.
0x16C RZB_SDR_Y_SAD_L — RESIZER B - OUTPUT MEMORY START ADDRESS REGISTER This register is used if the output data format is one of the following: RAW, YUV422, YUV420, RGB565, RGBA. RAW: RAW data is written to this address YUV422: YUV data is written to this address YUV420: Y data is written to this address RGB565: 16-bit RGB data is written to this address RGBA: 32-bit RGBA data is written to this address
  [15:0] Y_SAD_L rw — Memory Start Address Sets the 16 lower bits of the 32-bit start address in memory. It is a byte address. For every frame, the first line of data will be written to this address. We have: SAD = BAD + (PTR_S x OFT) and PTR_S PTR_E If the first line shall be written at the beginning of the circular buffer memory then SAD = BAD and PTR_S = 0. YUV420 format (output data on 8 bits): The two least significant bits shall be set to '00' when horizontal reversal mode is off. The two least significant bits shall be set to '11' when horizontal reversal mode is on. RAW, RGB565 and YUV422 formats (output data on 16 bits): The two least significant bits shall be set to '00' when horizontal reversal mode is off. The two least significant bits shall be set to '11' when horizontal reversal mode is on. RGBA format (output data on 32 bits): The three least significant bits shall be set to '000' when horizontal reversal mode is off. The three least significant bits shall be set to '111' when horizontal reversal mode is on.
0x170 RZB_SDR_Y_OFT — RESIZER B - OUTPUT MEMORY OFFSET REGISTER This register is used if the output data format is one of the following: RAW, YUV422, YUV420 or RGBA.
  fields as RZA_SDR_Y_OFT
0x174 RZB_SDR_Y_PTR_S — RESIZER B - OUTPUT MEMORY START ADDRESS REGISTER This register is used if the output data format is one of the following: RAW, YUV422, YUV420 or RGBA.
  fields as RZA_SDR_Y_PTR_S
0x178 RZB_SDR_Y_PTR_E — RESIZER B - OUTPUT MEMORY END ADDRESS REGISTER This register is used if the output data format is one of the following: RAW, YUV422, YUV420 or RGBA.
  fields as RZA_SDR_Y_PTR_E
0x17C RZB_SDR_C_BAD_H — RESIZER B - OUTPUT MEMORY BASE ADDRESS REGISTER FOR CHROMA DATA (YUV420) This register is used if the output data format is YUV420. U and V data are written into this buffer.
  [15:0] C_BAD_H rw — Memory Base Address Sets the 16 upper bits of the 32-bit base address of the circular buffer in memory.
0x180 RZB_SDR_C_BAD_L — RESIZER B - OUTPUT MEMORY BASE ADDRESS REGISTER FOR CHROMA DATA (YUV420) This register is used if the output data format is YUV420. U and V data are written into this buffer.
  fields as RZA_SDR_C_BAD_L
0x184 RZB_SDR_C_SAD_H — RESIZER B - OUTPUT MEMORY START ADDRESS REGISTER FOR CHROMA DATA (YUV420) This register is used if the output data format is YUV420. U and V data are written into this buffer.
  [15:0] C_SAD_H rw — Memory Base Address Sets the 16 upper bits of the 32-bit start address in memory.
0x188 RZB_SDR_C_SAD_L — RESIZER B - OUTPUT MEMORY START ADDRESS REGISTER FOR CHROMA DATA (YUV420) This register is used if the output data format is YUV420. U and V data are written into this buffer.
  [15:0] C_SAD_L rw — Memory Base Address Sets the 16 lower bits of the 32-bit start address in memory. It is a byte address. For every frame, the first line of data will be written to this address (C_SAD_H/C_SAD_L). We have: SAD = BAD + (PTR_S x OFT) and PTR_S PTR_E If the first line shall be written at the beginning of the circular buffer memory then SAD = BAD and PTR_S = 0. YUV420 format (output data on 8 bits): The two least significant bits shall be set to '00' when horizontal reversal mode is off. The two least significant bits shall be set to '11' when horizontal reversal mode is on.
0x18C RZB_SDR_C_OFT — RESIZER B - OUTPUT MEMORY OFFSET REGISTER FOR CHROMA DATA (YUV420) This register is used if the output data format is YUV420
  fields as RZA_SDR_C_OFT
0x190 RZB_SDR_C_PTR_S — RESIZER B - OUTPUT MEMORY START ADDRESS REGISTER FOR CHROMA DATA (YUV420) This register is used if the output data format is YUV420
  fields as RZA_SDR_C_PTR_S
0x194 RZB_SDR_C_PTR_E — RESIZER B - OUTPUT MEMORY END ADDRESS REGISTER FOR CHROMA DATA (YUV420) This register is used if the output data format is YUV420
  fields as RZA_SDR_C_PTR_E
